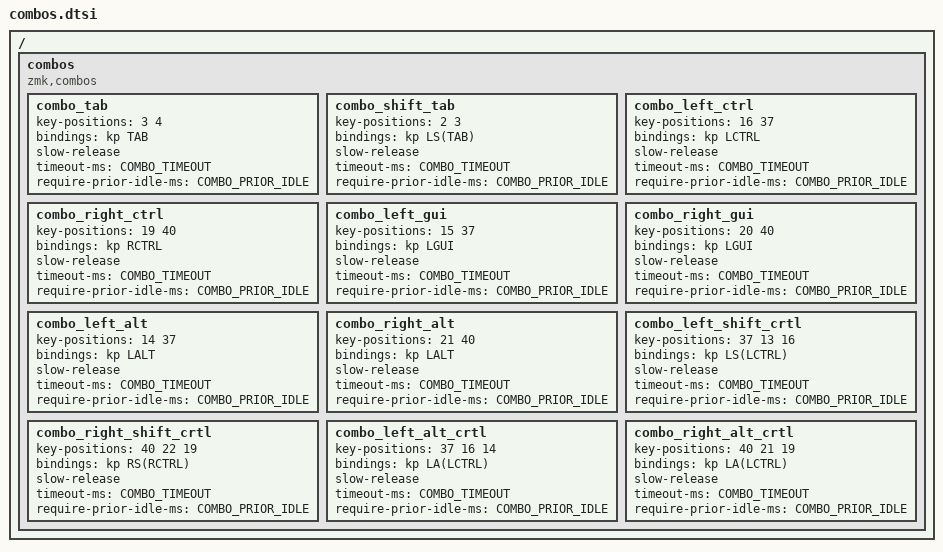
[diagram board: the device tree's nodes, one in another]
#define COMBO_TIMEOUT 40
#define COMBO_PRIOR_IDLE 50

/* KEY POSITIONS
  ╭─────────────────────────╮ ╭─────────────────────────╮
  │  0 │  1   2   3   4   5 │ │  6   7   8   9  10 │ 11 │
  │ 12 │ 13  14  15  16  17 │ │ 18  19  20  21  22 │ 23 │
  │ 24 │ 25  26  27  28  29 │ │ 30  31  32  33  34 │ 35 │
  ╰────────────╮ 36  37  38 │ │ 39  40  41 ╭────────────╯
               ╰────────────╯ ╰────────────╯
*/

/ {
  combos {
    compatible = "zmk,combos";

    combo_tab {
      key-positions = <3 4>;
      bindings = <&kp TAB>;
      slow-release;
      timeout-ms = <COMBO_TIMEOUT>;
      require-prior-idle-ms = <COMBO_PRIOR_IDLE>;
    };

    combo_shift_tab {
      key-positions = <2 3>;
      bindings = <&kp LS(TAB)>;
      slow-release;
      timeout-ms = <COMBO_TIMEOUT>;
      require-prior-idle-ms = <COMBO_PRIOR_IDLE>;
    };

    combo_left_ctrl {
      key-positions = <16 37>;
      bindings = <&kp LCTRL>;
      slow-release;
      timeout-ms = <COMBO_TIMEOUT>;
      require-prior-idle-ms = <COMBO_PRIOR_IDLE>;
    };

    combo_right_ctrl {
      key-positions = <19 40>;
      bindings = <&kp RCTRL>;
      slow-release;
      timeout-ms = <COMBO_TIMEOUT>;
      require-prior-idle-ms = <COMBO_PRIOR_IDLE>;
    };

    combo_left_gui {
      key-positions = <15 37>;
      bindings = <&kp LGUI>;
      slow-release;
      timeout-ms = <COMBO_TIMEOUT>;
      require-prior-idle-ms = <COMBO_PRIOR_IDLE>;
    };

    combo_right_gui {
      key-positions = <20 40>;
      bindings = <&kp LGUI>;
      slow-release;
      timeout-ms = <COMBO_TIMEOUT>;
      require-prior-idle-ms = <COMBO_PRIOR_IDLE>;
    };

    combo_left_alt {
      key-positions = <14 37>;
      bindings = <&kp LALT>;
      slow-release;
      timeout-ms = <COMBO_TIMEOUT>;
      require-prior-idle-ms = <COMBO_PRIOR_IDLE>;
    };

    combo_right_alt {
      key-positions = <21 40>;
      bindings = <&kp LALT>;
      slow-release;
      timeout-ms = <COMBO_TIMEOUT>;
      require-prior-idle-ms = <COMBO_PRIOR_IDLE>;
    };

    combo_left_shift_crtl {
      key-positions = <37 13 16>;
      bindings = <&kp LS(LCTRL)>;
      slow-release;
      timeout-ms = <COMBO_TIMEOUT>;
      require-prior-idle-ms = <COMBO_PRIOR_IDLE>;
    };

    combo_right_shift_crtl {
      key-positions = <40 22 19>;
      bindings = <&kp RS(RCTRL)>;
      slow-release;
      timeout-ms = <COMBO_TIMEOUT>;
      require-prior-idle-ms = <COMBO_PRIOR_IDLE>;
    };

    combo_left_alt_crtl {
      key-positions = <37 16 14>;
      bindings = <&kp LA(LCTRL)>;
      slow-release;
      timeout-ms = <COMBO_TIMEOUT>;
      require-prior-idle-ms = <COMBO_PRIOR_IDLE>;
    };

    combo_right_alt_crtl {
      key-positions = <40 21 19>;
      bindings = <&kp LA(LCTRL)>;
      slow-release;
      timeout-ms = <COMBO_TIMEOUT>;
      require-prior-idle-ms = <COMBO_PRIOR_IDLE>;
    };

  };
};
